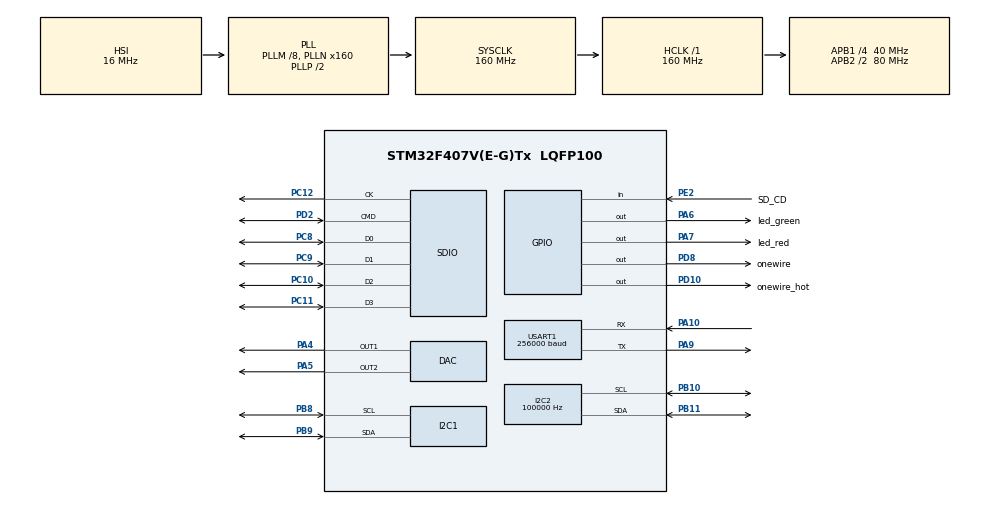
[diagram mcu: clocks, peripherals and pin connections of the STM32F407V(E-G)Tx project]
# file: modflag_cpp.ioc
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ADC1.Channel-0\#ChannelRegularConversion=ADC_CHANNEL_VBAT
ADC1.Channel-1\#ChannelRegularConversion=ADC_CHANNEL_TEMPSENSOR
ADC1.Channel-2\#ChannelRegularConversion=ADC_CHANNEL_VREFINT
ADC1.ContinuousConvMode=ENABLE
ADC1.DMAContinuousRequests=ENABLE
ADC1.EOCSelection=ADC_EOC_SEQ_CONV
ADC1.NbrOfConversion=3
ADC1.NbrOfConversionFlag=1
ADC1.Rank-0\#ChannelRegularConversion=1
ADC1.Rank-1\#ChannelRegularConversion=2
ADC1.Rank-2\#ChannelRegularConversion=3
ADC1.SamplingTime-0\#ChannelRegularConversion=ADC_SAMPLETIME_3CYCLES
ADC1.SamplingTime-1\#ChannelRegularConversion=ADC_SAMPLETIME_3CYCLES
ADC1.SamplingTime-2\#ChannelRegularConversion=ADC_SAMPLETIME_3CYCLES
ADC1.master=1
DAC.DAC_Trigger=DAC_TRIGGER_SOFTWARE
Dma.ADC1.1.Direction=DMA_PERIPH_TO_MEMORY
Dma.ADC1.1.FIFOMode=DMA_FIFOMODE_DISABLE
Dma.ADC1.1.Instance=DMA2_Stream0
Dma.ADC1.1.MemDataAlignment=DMA_MDATAALIGN_HALFWORD
Dma.ADC1.1.MemInc=DMA_MINC_ENABLE
Dma.ADC1.1.Mode=DMA_CIRCULAR
Dma.ADC1.1.PeriphDataAlignment=DMA_PDATAALIGN_HALFWORD
Dma.ADC1.1.PeriphInc=DMA_PINC_DISABLE
Dma.ADC1.1.Priority=DMA_PRIORITY_LOW
Dma.DAC1.0.Direction=DMA_MEMORY_TO_PERIPH
Dma.DAC1.0.FIFOMode=DMA_FIFOMODE_DISABLE
Dma.DAC1.0.Instance=DMA1_Stream5
Dma.DAC1.0.MemDataAlignment=DMA_MDATAALIGN_HALFWORD
Dma.DAC1.0.MemInc=DMA_MINC_ENABLE
Dma.DAC1.0.Mode=DMA_NORMAL
Dma.DAC1.0.PeriphDataAlignment=DMA_PDATAALIGN_HALFWORD
Dma.DAC1.0.PeriphInc=DMA_PINC_DISABLE
Dma.DAC1.0.Priority=DMA_PRIORITY_LOW
Dma.I2C1_RX.2.Direction=DMA_PERIPH_TO_MEMORY
Dma.I2C1_RX.2.FIFOMode=DMA_FIFOMODE_DISABLE
Dma.I2C1_RX.2.Instance=DMA1_Stream0
Dma.I2C1_RX.2.MemDataAlignment=DMA_MDATAALIGN_BYTE
Dma.I2C1_RX.2.MemInc=DMA_MINC_ENABLE
Dma.I2C1_RX.2.Mode=DMA_NORMAL
Dma.I2C1_RX.2.PeriphDataAlignment=DMA_PDATAALIGN_BYTE
Dma.I2C1_RX.2.PeriphInc=DMA_PINC_DISABLE
Dma.I2C1_RX.2.Priority=DMA_PRIORITY_LOW
Dma.I2C1_TX.3.Direction=DMA_MEMORY_TO_PERIPH
Dma.I2C1_TX.3.FIFOMode=DMA_FIFOMODE_DISABLE
Dma.I2C1_TX.3.Instance=DMA1_Stream6
Dma.I2C1_TX.3.MemDataAlignment=DMA_MDATAALIGN_BYTE
Dma.I2C1_TX.3.MemInc=DMA_MINC_ENABLE
Dma.I2C1_TX.3.Mode=DMA_NORMAL
Dma.I2C1_TX.3.PeriphDataAlignment=DMA_PDATAALIGN_BYTE
Dma.I2C1_TX.3.PeriphInc=DMA_PINC_DISABLE
Dma.I2C1_TX.3.Priority=DMA_PRIORITY_LOW
Dma.I2C2_RX.6.Direction=DMA_PERIPH_TO_MEMORY
Dma.I2C2_RX.6.FIFOMode=DMA_FIFOMODE_DISABLE
Dma.I2C2_RX.6.Instance=DMA1_Stream2
Dma.I2C2_RX.6.MemDataAlignment=DMA_MDATAALIGN_BYTE
Dma.I2C2_RX.6.MemInc=DMA_MINC_ENABLE
Dma.I2C2_RX.6.Mode=DMA_NORMAL
Dma.I2C2_RX.6.PeriphDataAlignment=DMA_PDATAALIGN_BYTE
Dma.I2C2_RX.6.PeriphInc=DMA_PINC_DISABLE
Dma.I2C2_RX.6.Priority=DMA_PRIORITY_LOW
Dma.I2C2_TX.7.Direction=DMA_MEMORY_TO_PERIPH
Dma.I2C2_TX.7.FIFOMode=DMA_FIFOMODE_DISABLE
Dma.I2C2_TX.7.Instance=DMA1_Stream7
Dma.I2C2_TX.7.MemDataAlignment=DMA_MDATAALIGN_BYTE
Dma.I2C2_TX.7.MemInc=DMA_MINC_ENABLE
Dma.I2C2_TX.7.Mode=DMA_NORMAL
Dma.I2C2_TX.7.PeriphDataAlignment=DMA_PDATAALIGN_BYTE
Dma.I2C2_TX.7.PeriphInc=DMA_PINC_DISABLE
Dma.I2C2_TX.7.Priority=DMA_PRIORITY_LOW
Dma.Request0=DAC1
Dma.Request1=ADC1
Dma.Request2=I2C1_RX
Dma.Request3=I2C1_TX
Dma.Request4=USART1_RX
Dma.Request5=USART1_TX
Dma.Request6=I2C2_RX
Dma.Request7=I2C2_TX
Dma.Request8=SDIO_RX
Dma.Request9=SDIO_TX
Dma.SDIO_RX.8.Direction=DMA_PERIPH_TO_MEMORY
Dma.SDIO_RX.8.FIFOMode=DMA_FIFOMODE_ENABLE
Dma.SDIO_RX.8.FIFOThreshold=DMA_FIFO_THRESHOLD_FULL
Dma.SDIO_RX.8.Instance=DMA2_Stream3
Dma.SDIO_RX.8.MemBurst=DMA_MBURST_INC4
Dma.SDIO_RX.8.MemDataAlignment=DMA_MDATAALIGN_WORD
Dma.SDIO_RX.8.MemInc=DMA_MINC_ENABLE
Dma.SDIO_RX.8.Mode=DMA_PFCTRL
Dma.SDIO_RX.8.PeriphBurst=DMA_PBURST_INC4
Dma.SDIO_RX.8.PeriphDataAlignment=DMA_PDATAALIGN_WORD
Dma.SDIO_RX.8.PeriphInc=DMA_PINC_DISABLE
Dma.SDIO_RX.8.Priority=DMA_PRIORITY_LOW
Dma.SDIO_TX.9.Direction=DMA_MEMORY_TO_PERIPH
Dma.SDIO_TX.9.FIFOMode=DMA_FIFOMODE_ENABLE
Dma.SDIO_TX.9.FIFOThreshold=DMA_FIFO_THRESHOLD_FULL
Dma.SDIO_TX.9.Instance=DMA2_Stream6
Dma.SDIO_TX.9.MemBurst=DMA_MBURST_INC4
Dma.SDIO_TX.9.MemDataAlignment=DMA_MDATAALIGN_WORD
Dma.SDIO_TX.9.MemInc=DMA_MINC_ENABLE
Dma.SDIO_TX.9.Mode=DMA_PFCTRL
Dma.SDIO_TX.9.PeriphBurst=DMA_PBURST_INC4
Dma.SDIO_TX.9.PeriphDataAlignment=DMA_PDATAALIGN_WORD
Dma.SDIO_TX.9.PeriphInc=DMA_PINC_DISABLE
Dma.SDIO_TX.9.Priority=DMA_PRIORITY_LOW
Dma.USART1_RX.4.Direction=DMA_PERIPH_TO_MEMORY
Dma.USART1_RX.4.FIFOMode=DMA_FIFOMODE_DISABLE
Dma.USART1_RX.4.Instance=DMA2_Stream2
Dma.USART1_RX.4.MemDataAlignment=DMA_MDATAALIGN_BYTE
Dma.USART1_RX.4.MemInc=DMA_MINC_ENABLE
Dma.USART1_RX.4.Mode=DMA_NORMAL
Dma.USART1_RX.4.PeriphDataAlignment=DMA_PDATAALIGN_BYTE
Dma.USART1_RX.4.PeriphInc=DMA_PINC_DISABLE
Dma.USART1_RX.4.Priority=DMA_PRIORITY_LOW
Dma.USART1_TX.5.Direction=DMA_MEMORY_TO_PERIPH
Dma.USART1_TX.5.FIFOMode=DMA_FIFOMODE_DISABLE
Dma.USART1_TX.5.Instance=DMA2_Stream7
Dma.USART1_TX.5.MemDataAlignment=DMA_MDATAALIGN_BYTE
Dma.USART1_TX.5.MemInc=DMA_MINC_ENABLE
Dma.USART1_TX.5.Mode=DMA_NORMAL
Dma.USART1_TX.5.PeriphDataAlignment=DMA_PDATAALIGN_BYTE
Dma.USART1_TX.5.PeriphInc=DMA_PINC_DISABLE
Dma.USART1_TX.5.Priority=DMA_PRIORITY_LOW
FATFS.BSP.number=1
FATFS.USE_DMA_CODE_SD=1
FATFS._MAX_LFN=32
FATFS._USE_LABEL=1
FATFS._USE_LFN=3
FATFS0.BSP.STBoard=false
FATFS0.BSP.api=Unknown
FATFS0.BSP.i2caddr=0
FATFS0.BSP.instance=PE2
FATFS0.BSP.ip=GPIO
FATFS0.BSP.mode=Input
FATFS0.BSP.name=Detect_SDIO
FATFS0.BSP.solution=PE2
I2C1.I2C_Mode=I2C_Standard
I2C2.ClockSpeed=100000
I2C2.I2C_Mode=I2C_Standard
Mcu.Family=STM32F4
Mcu.Name=STM32F407V(E-G)Tx
Mcu.Package=LQFP100
NVIC.ADC_IRQn=true\:0\:0\:false\:false\:true\:true\:true
NVIC.DMA1_Stream0_IRQn=true\:0\:0\:false\:false\:true\:false\:true
NVIC.DMA1_Stream2_IRQn=true\:0\:0\:false\:false\:true\:false\:true
NVIC.DMA1_Stream5_IRQn=true\:0\:0\:false\:false\:true\:false\:true
NVIC.DMA1_Stream6_IRQn=true\:0\:0\:false\:false\:true\:false\:true
NVIC.DMA1_Stream7_IRQn=true\:0\:0\:false\:false\:true\:false\:true
NVIC.DMA2_Stream0_IRQn=true\:0\:0\:false\:false\:true\:false\:true
NVIC.DMA2_Stream2_IRQn=true\:0\:0\:false\:false\:true\:false\:true
NVIC.DMA2_Stream3_IRQn=true\:0\:0\:false\:false\:true\:false\:true
NVIC.DMA2_Stream6_IRQn=true\:0\:0\:false\:false\:true\:false\:true
NVIC.DMA2_Stream7_IRQn=true\:0\:0\:false\:false\:true\:false\:true
NVIC.I2C1_ER_IRQn=true\:0\:0\:false\:false\:true\:true\:true
NVIC.I2C1_EV_IRQn=true\:0\:0\:false\:false\:true\:true\:true
NVIC.I2C2_ER_IRQn=true\:0\:0\:false\:false\:true\:true\:true
NVIC.I2C2_EV_IRQn=true\:0\:0\:false\:false\:true\:true\:true
NVIC.PriorityGroup=NVIC_PRIORITYGROUP_4
NVIC.SDIO_IRQn=true\:0\:0\:false\:false\:true\:true\:true
NVIC.TIM6_DAC_IRQn=true\:0\:0\:false\:false\:true\:true\:true
NVIC.USART1_IRQn=true\:0\:0\:false\:false\:true\:true\:true
PA10.Mode=Asynchronous
PA10.Signal=USART1_RX
PA13.Mode=Serial_Wire
PA13.Signal=SYS_JTMS-SWDIO
PA14.Mode=Serial_Wire
PA14.Signal=SYS_JTCK-SWCLK
PA4.Signal=COMP_DAC1_group
PA5.Signal=COMP_DAC2_group
PA6.GPIO_Label=led_green
PA6.GPIO_ModeDefaultOutputPP=GPIO_MODE_OUTPUT_OD
PA6.Signal=GPIO_Output
PA7.GPIO_Label=led_red
PA7.GPIO_ModeDefaultOutputPP=GPIO_MODE_OUTPUT_OD
PA7.Signal=GPIO_Output
PA9.Mode=Asynchronous
PA9.Signal=USART1_TX
PB10.Mode=I2C
PB10.Signal=I2C2_SCL
PB11.Mode=I2C
PB11.Signal=I2C2_SDA
PB8.GPIO_PuPdOD=GPIO_NOPULL
PB8.GPIO_Speed=GPIO_SPEED_FREQ_LOW
PB8.Mode=I2C
PB8.Signal=I2C1_SCL
PB9.GPIO_PuPdOD=GPIO_NOPULL
PB9.GPIO_Speed=GPIO_SPEED_FREQ_LOW
PB9.Mode=I2C
PB9.Signal=I2C1_SDA
PC10.Mode=SD_4_bits_Wide_bus
PC10.Signal=SDIO_D2
PC11.Mode=SD_4_bits_Wide_bus
PC11.Signal=SDIO_D3
PC12.Mode=SD_4_bits_Wide_bus
PC12.Signal=SDIO_CK
PC14-OSC32_IN.Mode=LSE-External-Oscillator
PC14-OSC32_IN.Signal=RCC_OSC32_IN
PC15-OSC32_OUT.Mode=LSE-External-Oscillator
PC15-OSC32_OUT.Signal=RCC_OSC32_OUT
PC8.Mode=SD_4_bits_Wide_bus
PC8.Signal=SDIO_D0
PC9.Mode=SD_4_bits_Wide_bus
PC9.Signal=SDIO_D1
PD10.GPIO_Label=onewire_hot
PD10.GPIO_ModeDefaultOutputPP=GPIO_MODE_OUTPUT_OD
PD10.Signal=GPIO_Output
PD2.Mode=SD_4_bits_Wide_bus
PD2.Signal=SDIO_CMD
PD8.GPIO_Label=onewire
PD8.GPIO_ModeDefaultOutputPP=GPIO_MODE_OUTPUT_OD
PD8.GPIO_Speed=GPIO_SPEED_FREQ_LOW
PD8.Signal=GPIO_Output
PE2.GPIO_Label=SD_CD
PE2.GPIO_PuPd=GPIO_PULLDOWN
PE2.Signal=GPIO_Input
PH0-OSC_IN.Mode=HSE-External-Oscillator
PH0-OSC_IN.Signal=RCC_OSC_IN
PH1-OSC_OUT.Mode=HSE-External-Oscillator
PH1-OSC_OUT.Signal=RCC_OSC_OUT
ProjectManager.HeapSize=0x8000
ProjectManager.StackSize=0x400
ProjectManager.TargetToolchain=STM32CubeIDE
RCC.48MHZClocksFreq_Value=45714285.71428572
RCC.AHBFreq_Value=160000000
RCC.APB1CLKDivider=RCC_HCLK_DIV4
RCC.APB1Freq_Value=40000000
RCC.APB1TimFreq_Value=80000000
RCC.APB2CLKDivider=RCC_HCLK_DIV2
RCC.APB2Freq_Value=80000000
RCC.APB2TimFreq_Value=160000000
RCC.CortexFreq_Value=160000000
RCC.HCLKFreq_Value=160000000
RCC.HSE_VALUE=8000000
RCC.HSI_VALUE=16000000
RCC.PLLM=8
RCC.PLLN=160
RCC.PLLQ=7
RCC.RCC_RTC_Clock_Source=RCC_RTCCLKSOURCE_LSE
RCC.RCC_RTC_Clock_SourceVirtual=RCC_RTCCLKSOURCE_LSE
RCC.SYSCLKFreq_VALUE=160000000
RCC.SYSCLKSource=RCC_SYSCLKSOURCE_PLLCLK
RCC.VCOOutputFreq_Value=320000000
RTC.Date=15
RTC.Format=RTC_FORMAT_BIN
RTC.Hours=19
RTC.Minutes=16
RTC.Month=RTC_MONTH_NOVEMBER
RTC.WeekDay=RTC_WEEKDAY_SUNDAY
RTC.Year=20
SDIO.ClockDiv=0
SDIO.HardwareFlowControl=SDIO_HARDWARE_FLOW_CONTROL_DISABLE
SH.COMP_DAC1_group.0=DAC_OUT1,DAC_OUT1
SH.COMP_DAC2_group.0=DAC_OUT2,DAC_OUT2
TIM2.AutoReloadPreload=TIM_AUTORELOAD_PRELOAD_ENABLE
TIM6.AutoReloadPreload=TIM_AUTORELOAD_PRELOAD_ENABLE
TIM6.Period=1600
TIM6.Prescaler=1
TIM6.TIM_MasterOutputTrigger=TIM_TRGO_UPDATE
USART1.BaudRate=256000
USART1.VirtualMode=VM_ASYNC
VP_ADC1_TempSens_Input.Mode=IN-TempSens
VP_ADC1_Vbat_Input.Mode=IN-Vbat
VP_ADC1_Vref_Input.Mode=IN-Vrefint
VP_FATFS_VS_SDIO.Mode=SDIO
VP_RTC_VS_RTC_Activate.Mode=RTC_Enabled
VP_RTC_VS_RTC_Calendar.Mode=RTC_Calendar
VP_TIM2_VS_ClockSourceINT.Mode=Internal
VP_TIM6_VS_ClockSourceINT.Mode=Enable_Timer
board=custom

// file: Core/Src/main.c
/* USER CODE BEGIN Header */
/**
  ******************************************************************************
  * @file           : main.c
  * @brief          : Main program body
  ******************************************************************************
  * @attention
  *
  * <h2><center>&copy; Copyright (c) 2020 STMicroelectronics.
  * All rights reserved.</center></h2>
  *
  * This software component is licensed by ST under Ultimate Liberty license
  * SLA0044, the "License"; You may not use this file except in compliance with
  * the License. You may obtain a copy of the License at:
  *                             www.st.com/SLA0044
  *
  ******************************************************************************
  */
/* USER CODE END Header */
#include "main.h"
#include "adc.h"
#include "dac.h"
#include "dma.h"
#include "fatfs.h"
#include "i2c.h"
#include "rtc.h"
#include "sdio.h"
#include "tim.h"
#include "usart.h"
#include "gpio.h"

/* USER CODE BEGIN Includes */

#include "cpp_link.hpp"
/* USER CODE END Includes */

void SystemClock_Config(void);

int main(void)
{

  /* MCU Configuration--------------------------------------------------------*/

  /* Reset of all peripherals, Initializes the Flash interface and the Systick. */
  HAL_Init();

  /* Configure the system clock */
  SystemClock_Config();

  /* Initialize all configured peripherals */
  MX_GPIO_Init();
  MX_DMA_Init();
  MX_RTC_Init();
  MX_SDIO_SD_Init();
  MX_TIM6_Init();
  MX_USART1_UART_Init();
  MX_DAC_Init();
  MX_TIM2_Init();
  MX_I2C1_Init();
  MX_ADC1_Init();
  MX_I2C2_Init();
  MX_FATFS_Init();

  /* Infinite loop */
  /* USER CODE BEGIN WHILE */

      cpp_init();

  while (1)
  {
      cpp_tasks();
    /* USER CODE END WHILE */

  }
}

void SystemClock_Config(void)
{
  RCC_OscInitTypeDef RCC_OscInitStruct = {0};
  RCC_ClkInitTypeDef RCC_ClkInitStruct = {0};
  RCC_PeriphCLKInitTypeDef PeriphClkInitStruct = {0};

  /** Configure the main internal regulator output voltage
  */
  __HAL_RCC_PWR_CLK_ENABLE();
  __HAL_PWR_VOLTAGESCALING_CONFIG(PWR_REGULATOR_VOLTAGE_SCALE1);
  /** Initializes the RCC Oscillators according to the specified parameters
  * in the RCC_OscInitTypeDef structure.
  */
  RCC_OscInitStruct.OscillatorType = RCC_OSCILLATORTYPE_HSI|RCC_OSCILLATORTYPE_LSE;
  RCC_OscInitStruct.LSEState = RCC_LSE_ON;
  RCC_OscInitStruct.HSIState = RCC_HSI_ON;
  RCC_OscInitStruct.HSICalibrationValue = RCC_HSICALIBRATION_DEFAULT;
  RCC_OscInitStruct.PLL.PLLState = RCC_PLL_ON;
  RCC_OscInitStruct.PLL.PLLSource = RCC_PLLSOURCE_HSI;
  RCC_OscInitStruct.PLL.PLLM = 8;
  RCC_OscInitStruct.PLL.PLLN = 160;
  RCC_OscInitStruct.PLL.PLLP = RCC_PLLP_DIV2;
  RCC_OscInitStruct.PLL.PLLQ = 7;
  if (HAL_RCC_OscConfig(&RCC_OscInitStruct) != HAL_OK)
  {
    Error_Handler();
  }
  /** Initializes the CPU, AHB and APB buses clocks
  */
  RCC_ClkInitStruct.ClockType = RCC_CLOCKTYPE_HCLK|RCC_CLOCKTYPE_SYSCLK
                              |RCC_CLOCKTYPE_PCLK1|RCC_CLOCKTYPE_PCLK2;
  RCC_ClkInitStruct.SYSCLKSource = RCC_SYSCLKSOURCE_PLLCLK;
  RCC_ClkInitStruct.AHBCLKDivider = RCC_SYSCLK_DIV1;
  RCC_ClkInitStruct.APB1CLKDivider = RCC_HCLK_DIV4;
  RCC_ClkInitStruct.APB2CLKDivider = RCC_HCLK_DIV2;

  if (HAL_RCC_ClockConfig(&RCC_ClkInitStruct, FLASH_LATENCY_5) != HAL_OK)
  {
    Error_Handler();
  }
  PeriphClkInitStruct.PeriphClockSelection = RCC_PERIPHCLK_RTC;
  PeriphClkInitStruct.RTCClockSelection = RCC_RTCCLKSOURCE_LSE;
  if (HAL_RCCEx_PeriphCLKConfig(&PeriphClkInitStruct) != HAL_OK)
  {
    Error_Handler();
  }
}

void Error_Handler(void)
{
  __disable_irq();
  while (1)
  {
  }
}

/************************ (C) COPYRIGHT STMicroelectronics *****END OF FILE****/
